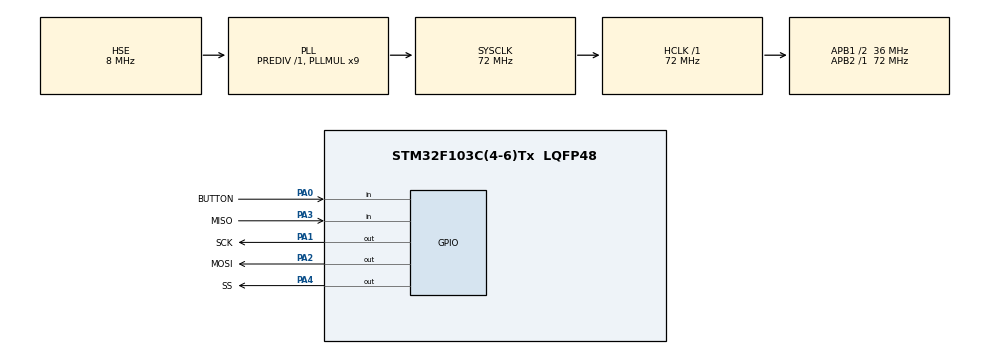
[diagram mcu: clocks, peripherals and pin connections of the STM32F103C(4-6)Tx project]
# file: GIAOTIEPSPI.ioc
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Mcu.Family=STM32F1
Mcu.Name=STM32F103C(4-6)Tx
Mcu.Package=LQFP48
NVIC.PriorityGroup=NVIC_PRIORITYGROUP_4
PA0-WKUP.GPIO_Label=BUTTON
PA0-WKUP.GPIO_PuPd=GPIO_PULLUP
PA0-WKUP.Signal=GPIO_Input
PA1.GPIO_Label=SCK
PA1.Signal=GPIO_Output
PA13.Mode=Serial_Wire
PA13.Signal=SYS_JTMS-SWDIO
PA14.Mode=Serial_Wire
PA14.Signal=SYS_JTCK-SWCLK
PA2.GPIO_Label=MOSI
PA2.Signal=GPIO_Output
PA3.GPIO_Label=MISO
PA3.Signal=GPIO_Input
PA4.GPIO_Label=SS
PA4.Signal=GPIO_Output
PD0-OSC_IN.Mode=HSE-External-Oscillator
PD0-OSC_IN.Signal=RCC_OSC_IN
PD1-OSC_OUT.Mode=HSE-External-Oscillator
PD1-OSC_OUT.Signal=RCC_OSC_OUT
ProjectManager.HeapSize=0x200
ProjectManager.StackSize=0x400
ProjectManager.TargetToolchain=MDK-ARM V5.32
RCC.AHBFreq_Value=72000000
RCC.APB1CLKDivider=RCC_HCLK_DIV2
RCC.APB1Freq_Value=36000000
RCC.APB1TimFreq_Value=72000000
RCC.APB2Freq_Value=72000000
RCC.APB2TimFreq_Value=72000000
RCC.HCLKFreq_Value=72000000
RCC.PLLMUL=RCC_PLL_MUL9
RCC.PLLSourceVirtual=RCC_PLLSOURCE_HSE
RCC.SYSCLKFreq_VALUE=72000000
RCC.SYSCLKSource=RCC_SYSCLKSOURCE_PLLCLK
RCC.USBFreq_Value=72000000
board=custom

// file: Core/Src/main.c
/* USER CODE BEGIN Header */
/**
  ******************************************************************************
  * @file           : main.c
  * @brief          : Main program body
  ******************************************************************************
  * @attention
  *
  * Copyright (c) 2022 STMicroelectronics.
  * All rights reserved.
  *
  * This software is licensed under terms that can be found in the LICENSE file
  * in the root directory of this software component.
  * If no LICENSE file comes with this software, it is provided AS-IS.
  *
  ******************************************************************************
  */
/* USER CODE END Header */
#include "main.h"

void SystemClock_Config(void);
static void MX_GPIO_Init(void);

	void SPI_Soft_init();// chuong trình kh?i t?o SPI
void Clock();// chuong trình t?o 1 xung clock
void SPI_Soft_Transmit(uint8_t mData);// chuong trình g?i 1 byte
uint8_t SPI_Soft_Receive();// chuong trình nh?n v? 1 byte
int main(void)
{

  /* MCU Configuration--------------------------------------------------------*/

  /* Reset of all peripherals, Initializes the Flash interface and the Systick. */
  HAL_Init();

  /* Configure the system clock */
  SystemClock_Config();

  /* Initialize all configured peripherals */
  MX_GPIO_Init();
  /* USER CODE BEGIN 2 */
SPI_Soft_init();
  /* USER CODE END 2 */

  /* Infinite loop */
  while (1)
  {
    /* USER CODE BEGIN 3 */
		if(HAL_GPIO_ReadPin(BUTTON_GPIO_Port,BUTTON_Pin)==0)
		{
			SPI_Soft_Transmit(0xf0);

  }
  /* USER CODE END 3 */
}
}
void SPI_Soft_init(){
  HAL_GPIO_WritePin(SCK_GPIO_Port,SCK_Pin,0);
   HAL_GPIO_WritePin(MOSI_GPIO_Port,MOSI_Pin,0);
   HAL_GPIO_WritePin(SS_GPIO_Port,SS_Pin,1);
}
void Clock(){
 HAL_GPIO_WritePin(SCK_GPIO_Port,SCK_Pin,1);
  HAL_Delay(10);
  HAL_GPIO_WritePin(SCK_GPIO_Port,SCK_Pin,0);
  HAL_Delay(10);
}
void SPI_Soft_Transmit(uint8_t mData){
  uint8_t i = 0, x = 0;
  HAL_GPIO_WritePin(SS_GPIO_Port,SS_Pin,0);
  for(i = 0; i < 8; i++){ x = mData&0x80; // dua bit c?n truy?n lên chân MOSI
		if(x>0)
       HAL_GPIO_WritePin(MOSI_GPIO_Port,MOSI_Pin,1);
    else
      HAL_GPIO_WritePin(MOSI_GPIO_Port,MOSI_Pin,0);
    Clock(); // phát 1 xung clock g?i d? li?u di
    mData=mData<<1; // d?ch d? li?u c?n g?i lên 1 bits
  }
  HAL_GPIO_WritePin(SS_GPIO_Port,SS_Pin,1);//Ðã g?i xong,dua chân SS lên m?c 1
}
uint8_t SPI_Soft_Receive(){
  uint8_t _data=0x00, i=0;
  while(i<8){
    _data = _data<<1;       // d?ch d? li?u lên 1 bit
    _data = _data | MISO_Pin;    //d?c chân MISO
    Clock();                // phát m?t xung clock d? d?c bit ti?p theo
  }
  return _data;             // tr? v? d? li?u d?c du?c
}
void SystemClock_Config(void)
{
  RCC_OscInitTypeDef RCC_OscInitStruct = {0};
  RCC_ClkInitTypeDef RCC_ClkInitStruct = {0};

  /** Initializes the RCC Oscillators according to the specified parameters
  * in the RCC_OscInitTypeDef structure.
  */
  RCC_OscInitStruct.OscillatorType = RCC_OSCILLATORTYPE_HSE;
  RCC_OscInitStruct.HSEState = RCC_HSE_ON;
  RCC_OscInitStruct.HSEPredivValue = RCC_HSE_PREDIV_DIV1;
  RCC_OscInitStruct.HSIState = RCC_HSI_ON;
  RCC_OscInitStruct.PLL.PLLState = RCC_PLL_ON;
  RCC_OscInitStruct.PLL.PLLSource = RCC_PLLSOURCE_HSE;
  RCC_OscInitStruct.PLL.PLLMUL = RCC_PLL_MUL9;
  if (HAL_RCC_OscConfig(&RCC_OscInitStruct) != HAL_OK)
  {
    Error_Handler();
  }

  /** Initializes the CPU, AHB and APB buses clocks
  */
  RCC_ClkInitStruct.ClockType = RCC_CLOCKTYPE_HCLK|RCC_CLOCKTYPE_SYSCLK
                              |RCC_CLOCKTYPE_PCLK1|RCC_CLOCKTYPE_PCLK2;
  RCC_ClkInitStruct.SYSCLKSource = RCC_SYSCLKSOURCE_PLLCLK;
  RCC_ClkInitStruct.AHBCLKDivider = RCC_SYSCLK_DIV1;
  RCC_ClkInitStruct.APB1CLKDivider = RCC_HCLK_DIV2;
  RCC_ClkInitStruct.APB2CLKDivider = RCC_HCLK_DIV1;

  if (HAL_RCC_ClockConfig(&RCC_ClkInitStruct, FLASH_LATENCY_2) != HAL_OK)
  {
    Error_Handler();
  }
}

static void MX_GPIO_Init(void)
{
  GPIO_InitTypeDef GPIO_InitStruct = {0};

  /* GPIO Ports Clock Enable */
  __HAL_RCC_GPIOD_CLK_ENABLE();
  __HAL_RCC_GPIOA_CLK_ENABLE();

  /*Configure GPIO pin Output Level */
  HAL_GPIO_WritePin(GPIOA, GPIO_PIN_1|GPIO_PIN_2|GPIO_PIN_4, GPIO_PIN_RESET);

  /*Configure GPIO pin : PA0 */
  GPIO_InitStruct.Pin = GPIO_PIN_0;
  GPIO_InitStruct.Mode = GPIO_MODE_INPUT;
  GPIO_InitStruct.Pull = GPIO_PULLUP;
  HAL_GPIO_Init(GPIOA, &GPIO_InitStruct);

  /*Configure GPIO pins : PA1 PA2 PA4 */
  GPIO_InitStruct.Pin = GPIO_PIN_1|GPIO_PIN_2|GPIO_PIN_4;
  GPIO_InitStruct.Mode = GPIO_MODE_OUTPUT_PP;
  GPIO_InitStruct.Pull = GPIO_NOPULL;
  GPIO_InitStruct.Speed = GPIO_SPEED_FREQ_LOW;
  HAL_GPIO_Init(GPIOA, &GPIO_InitStruct);

  /*Configure GPIO pin : PA3 */
  GPIO_InitStruct.Pin = GPIO_PIN_3;
  GPIO_InitStruct.Mode = GPIO_MODE_INPUT;
  GPIO_InitStruct.Pull = GPIO_NOPULL;
  HAL_GPIO_Init(GPIOA, &GPIO_InitStruct);

}

void Error_Handler(void)
{
  __disable_irq();
  while (1)
  {
  }
}
